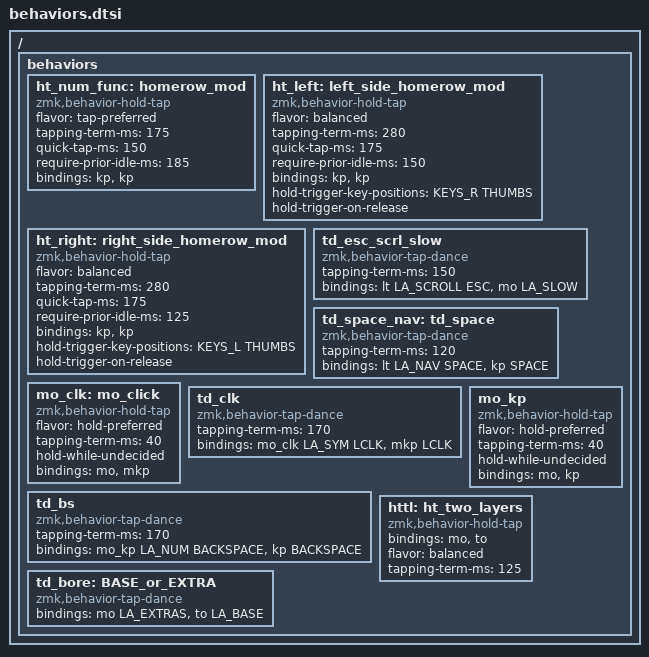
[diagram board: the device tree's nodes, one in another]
#define KEYS_L 0 1 2 3 4 5 12 13 14 15 16 17 24 25 26 27 28 29 36 37 38 19 20 21 22  // Left-hand keys.
#define KEYS_R 6 7 8 9 10 11 18 19 20 21 22 23 30 31 32 33 34 35 39 40 16 15 14 13  // Right-hand keys.
#define THUMBS 36 37 38 39 40  // Thumb keys.
#include "layers.dtsi"

/ {
    behaviors {
        ht_num_func: homerow_mod {
            compatible = "zmk,behavior-hold-tap";
            #binding-cells = <2>;
            flavor = "tap-preferred";
            tapping-term-ms = <175>; // triggers the hold behavior when the tapping-term-ms has expired
            quick-tap-ms = <150>; // If you press a tapped hold-tap again within quick-tap-ms milliseconds of the first press, it will always trigger the tap behavior.
            require-prior-idle-ms = <185>; // like quick-tap-ms however it will apply for any non-modifier key pressed before it
            bindings = <&kp>, <&kp>;  // hold, tap
        };

        // Left-hand HRM
        ht_left: left_side_homerow_mod {
            compatible = "zmk,behavior-hold-tap";
            #binding-cells = <2>;
            flavor = "balanced";
            tapping-term-ms = <280>;
            quick-tap-ms = <175>;
            require-prior-idle-ms = <150>;
            bindings = <&kp>, <&kp>;
            hold-trigger-key-positions = <KEYS_R THUMBS>;
            hold-trigger-on-release;
        };

        // Right-hand HRM
        ht_right: right_side_homerow_mod {
            compatible = "zmk,behavior-hold-tap";
            #binding-cells = <2>;
            flavor = "balanced";
            tapping-term-ms = <280>;
            quick-tap-ms = <175>;
            require-prior-idle-ms = <125>;
            bindings = <&kp>, <&kp>;
            hold-trigger-key-positions = <KEYS_L THUMBS>;
            hold-trigger-on-release;
        };

        td_esc_scrl_slow: td_esc_scrl_slow {
            compatible = "zmk,behavior-tap-dance";
            #binding-cells = <0>;
            tapping-term-ms = <150>;
            bindings = <&lt LA_SCROLL ESC>, <&mo LA_SLOW>; // hold, tap, double_tap
        };

        td_space_nav: td_space {
            compatible = "zmk,behavior-tap-dance";
            #binding-cells = <0>;
            tapping-term-ms = <120>;
            bindings = <&lt LA_NAV SPACE>, <&kp SPACE>; // hold, tap, double_tap
        };

        mo_clk: mo_click {
            compatible = "zmk,behavior-hold-tap";
            #binding-cells = <2>;
            flavor = "hold-preferred";
            tapping-term-ms = <40>;
            hold-while-undecided;
            bindings = <&mo>, <&mkp>;
        };

        td_clk: td_clk {
            compatible = "zmk,behavior-tap-dance";
            #binding-cells = <0>;
            tapping-term-ms = <170>;
            bindings = <&mo_clk LA_SYM LCLK>, <&mkp LCLK>; // hold, tap, double_tap
        };

        mo_kp: mo_kp {
            compatible = "zmk,behavior-hold-tap";
            #binding-cells = <2>;
            flavor       = "hold-preferred";
            tapping-term-ms = <40>;
            hold-while-undecided;
            bindings = <&mo>, <&kp>;
        };

        td_bs: td_bs {
            compatible = "zmk,behavior-tap-dance";
            #binding-cells = <0>;
            tapping-term-ms = <170>;
            bindings = <&mo_kp LA_NUM BACKSPACE>, <&kp BACKSPACE>; // hold, tap, double_tap
        };

        httl: ht_two_layers {
            compatible = "zmk,behavior-hold-tap";
            bindings = <&mo>, <&to>;
            #binding-cells = <2>;
            flavor = "balanced";
            tapping-term-ms = <125>;
        };

        td_bore: BASE_or_EXTRA {
            compatible = "zmk,behavior-tap-dance";
            #binding-cells = <0>;
            bindings = <&mo LA_EXTRAS>, <&to LA_BASE>;
        };
    };
};
